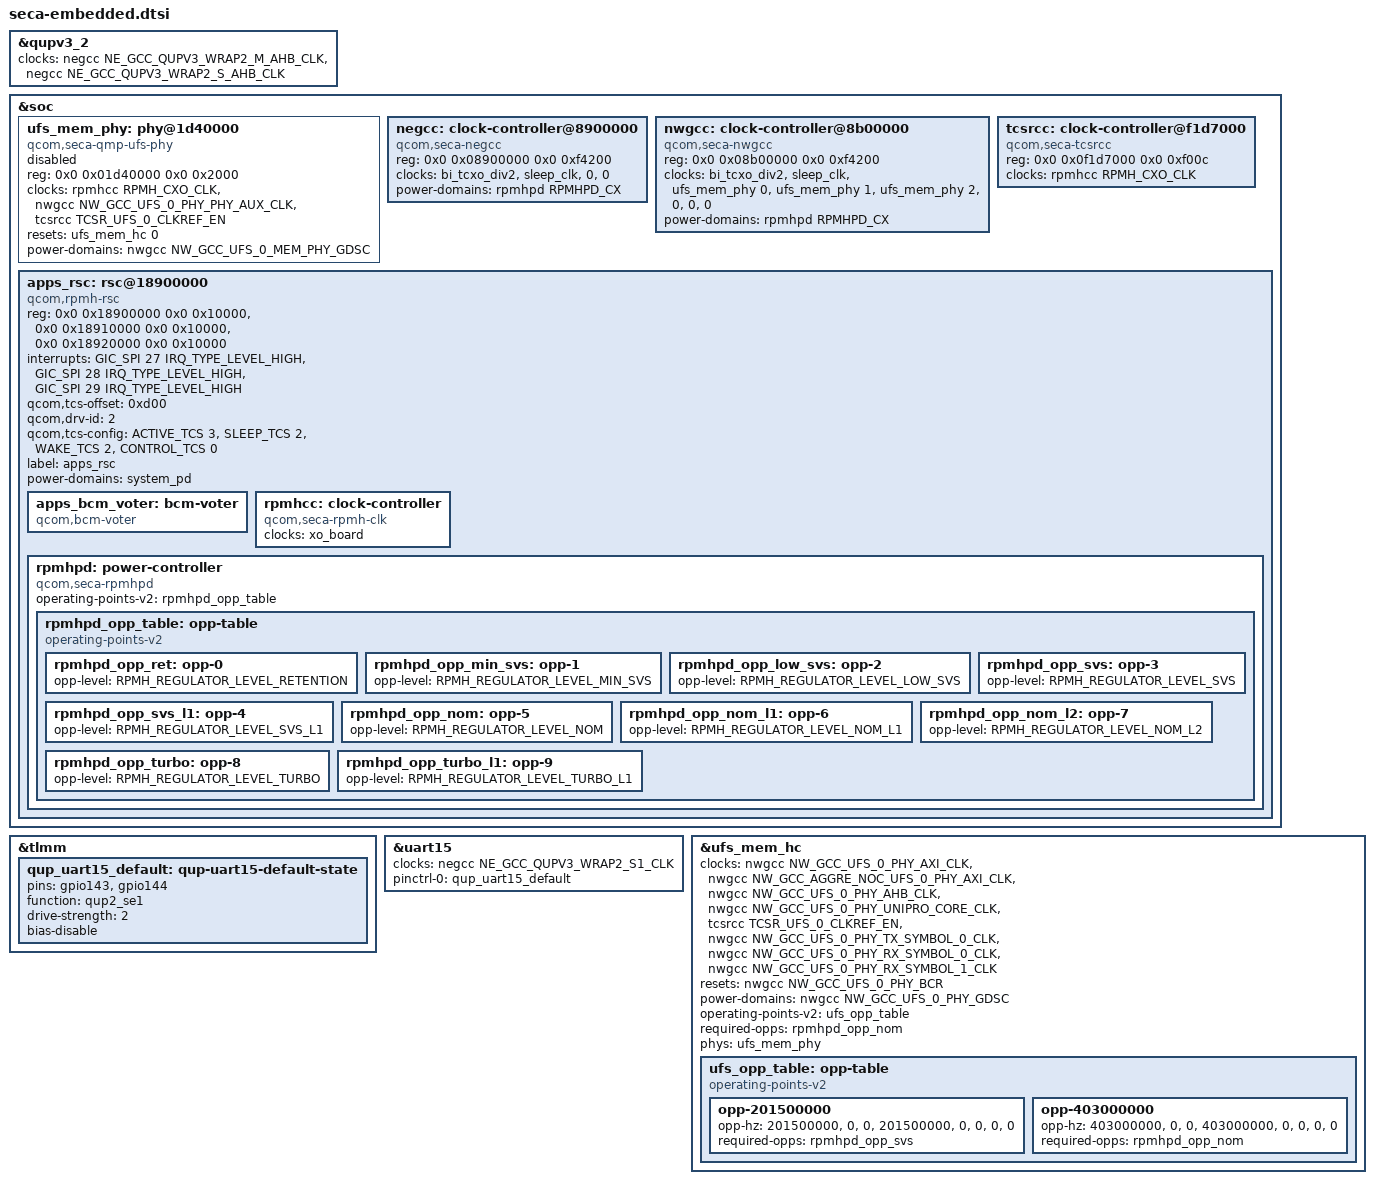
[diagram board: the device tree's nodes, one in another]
// SPDX-License-Identifier: BSD-3-Clause
/*
 * Copyright (c) Qualcomm Technologies, Inc. and/or its subsidiaries.
 */

#include <dt-bindings/clock/qcom,rpmh.h>
#include <dt-bindings/clock/qcom,seca-negcc.h>
#include <dt-bindings/clock/qcom,seca-nwgcc.h>
#include <dt-bindings/clock/qcom,seca-tcsrcc.h>
#include <dt-bindings/power/qcom,rpmhpd.h>
#include <dt-bindings/soc/qcom,rpmh-rsc.h>

#include "seca.dtsi"

&qupv3_2 {
	clocks = <&negcc NE_GCC_QUPV3_WRAP2_M_AHB_CLK>,
		 <&negcc NE_GCC_QUPV3_WRAP2_S_AHB_CLK>;
	clock-names = "m-ahb",
		      "s-ahb";
};

&soc {
	ufs_mem_phy: phy@1d40000 {
		compatible = "qcom,seca-qmp-ufs-phy",
			     "qcom,sm8650-qmp-ufs-phy";
		reg = <0x0 0x01d40000 0x0 0x2000>;

		clocks = <&rpmhcc RPMH_CXO_CLK>,
			 <&nwgcc NW_GCC_UFS_0_PHY_PHY_AUX_CLK>,
			 <&tcsrcc TCSR_UFS_0_CLKREF_EN>;
		clock-names = "ref",
			      "ref_aux",
			      "qref";

		resets = <&ufs_mem_hc 0>;
		reset-names = "ufsphy";

		power-domains = <&nwgcc NW_GCC_UFS_0_MEM_PHY_GDSC>;

		#clock-cells = <1>;
		#phy-cells = <0>;

		status = "disabled";
	};

	negcc: clock-controller@8900000 {
		compatible = "qcom,seca-negcc";
		reg = <0x0 0x08900000 0x0 0xf4200>;
		clocks = <&bi_tcxo_div2>,
			 <&sleep_clk>,
			 <0>,
			 <0>;
		power-domains = <&rpmhpd RPMHPD_CX>;
		#clock-cells = <1>;
		#reset-cells = <1>;
		#power-domain-cells = <1>;
	};

	nwgcc: clock-controller@8b00000 {
		compatible = "qcom,seca-nwgcc";
		reg = <0x0 0x08b00000 0x0 0xf4200>;
		clocks = <&bi_tcxo_div2>,
			 <&sleep_clk>,
			 <&ufs_mem_phy 0>,
			 <&ufs_mem_phy 1>,
			 <&ufs_mem_phy 2>,
			 <0>,
			 <0>,
			 <0>;
		power-domains = <&rpmhpd RPMHPD_CX>;
		#clock-cells = <1>;
		#reset-cells = <1>;
		#power-domain-cells = <1>;
	};

	tcsrcc: clock-controller@f1d7000 {
		compatible = "qcom,seca-tcsrcc";
		reg = <0x0 0x0f1d7000 0x0 0xf00c>;
		clocks = <&rpmhcc RPMH_CXO_CLK>;
		#clock-cells = <1>;
	};

	apps_rsc: rsc@18900000 {
		compatible = "qcom,rpmh-rsc";
		reg = <0x0 0x18900000 0x0 0x10000>,
		      <0x0 0x18910000 0x0 0x10000>,
		      <0x0 0x18920000 0x0 0x10000>;
		reg-names = "drv-0",
			    "drv-1",
			    "drv-2";
		interrupts = <GIC_SPI 27 IRQ_TYPE_LEVEL_HIGH>,
			     <GIC_SPI 28 IRQ_TYPE_LEVEL_HIGH>,
			     <GIC_SPI 29 IRQ_TYPE_LEVEL_HIGH>;
		qcom,tcs-offset = <0xd00>;
		qcom,drv-id = <2>;
		qcom,tcs-config = <ACTIVE_TCS 3>,
				  <SLEEP_TCS 2>,
				  <WAKE_TCS 2>,
				  <CONTROL_TCS 0>;
		label = "apps_rsc";
		power-domains = <&system_pd>;

		apps_bcm_voter: bcm-voter {
			compatible = "qcom,bcm-voter";
		};

		rpmhcc: clock-controller {
			compatible = "qcom,seca-rpmh-clk";
			clocks = <&xo_board>;
			clock-names = "xo";
			#clock-cells = <1>;
		};

		rpmhpd: power-controller {
			compatible = "qcom,seca-rpmhpd";
			#power-domain-cells = <1>;
			operating-points-v2 = <&rpmhpd_opp_table>;

			rpmhpd_opp_table: opp-table {
				compatible = "operating-points-v2";

				rpmhpd_opp_ret: opp-0 {
					opp-level = <RPMH_REGULATOR_LEVEL_RETENTION>;
				};

				rpmhpd_opp_min_svs: opp-1 {
					opp-level = <RPMH_REGULATOR_LEVEL_MIN_SVS>;
				};

				rpmhpd_opp_low_svs: opp-2 {
					opp-level = <RPMH_REGULATOR_LEVEL_LOW_SVS>;
				};

				rpmhpd_opp_svs: opp-3 {
					opp-level = <RPMH_REGULATOR_LEVEL_SVS>;
				};

				rpmhpd_opp_svs_l1: opp-4 {
					opp-level = <RPMH_REGULATOR_LEVEL_SVS_L1>;
				};

				rpmhpd_opp_nom: opp-5 {
					opp-level = <RPMH_REGULATOR_LEVEL_NOM>;
				};

				rpmhpd_opp_nom_l1: opp-6 {
					opp-level = <RPMH_REGULATOR_LEVEL_NOM_L1>;
				};

				rpmhpd_opp_nom_l2: opp-7 {
					opp-level = <RPMH_REGULATOR_LEVEL_NOM_L2>;
				};

				rpmhpd_opp_turbo: opp-8 {
					opp-level = <RPMH_REGULATOR_LEVEL_TURBO>;
				};

				rpmhpd_opp_turbo_l1: opp-9 {
					opp-level = <RPMH_REGULATOR_LEVEL_TURBO_L1>;
				};
			};
		};
	};
};

&tlmm {
	qup_uart15_default: qup-uart15-default-state {
		pins = "gpio143", "gpio144";
		function = "qup2_se1";
		drive-strength = <2>;
		bias-disable;
	};
};

&uart15 {
	clocks = <&negcc NE_GCC_QUPV3_WRAP2_S1_CLK>;
	clock-names = "se";

	pinctrl-0 = <&qup_uart15_default>;
	pinctrl-names = "default";
};

&ufs_mem_hc {
	clocks = <&nwgcc NW_GCC_UFS_0_PHY_AXI_CLK>,
		 <&nwgcc NW_GCC_AGGRE_NOC_UFS_0_PHY_AXI_CLK>,
		 <&nwgcc NW_GCC_UFS_0_PHY_AHB_CLK>,
		 <&nwgcc NW_GCC_UFS_0_PHY_UNIPRO_CORE_CLK>,
		 <&tcsrcc TCSR_UFS_0_CLKREF_EN>,
		 <&nwgcc NW_GCC_UFS_0_PHY_TX_SYMBOL_0_CLK>,
		 <&nwgcc NW_GCC_UFS_0_PHY_RX_SYMBOL_0_CLK>,
		 <&nwgcc NW_GCC_UFS_0_PHY_RX_SYMBOL_1_CLK>;
	clock-names = "core_clk",
		      "bus_aggr_clk",
		      "iface_clk",
		      "core_clk_unipro",
		      "ref_clk",
		      "tx_lane0_sync_clk",
		      "rx_lane0_sync_clk",
		      "rx_lane1_sync_clk";

	resets = <&nwgcc NW_GCC_UFS_0_PHY_BCR>;
	reset-names = "rst";

	power-domains = <&nwgcc NW_GCC_UFS_0_PHY_GDSC>;
	operating-points-v2 = <&ufs_opp_table>;
	required-opps = <&rpmhpd_opp_nom>;

	phys = <&ufs_mem_phy>;
	phy-names = "ufsphy";

	#reset-cells = <1>;

	ufs_opp_table: opp-table {
		compatible = "operating-points-v2";

		opp-201500000 {
			opp-hz = /bits/ 64 <201500000>,
				 /bits/ 64 <0>,
				 /bits/ 64 <0>,
				 /bits/ 64 <201500000>,
				 /bits/ 64 <0>,
				 /bits/ 64 <0>,
				 /bits/ 64 <0>,
				 /bits/ 64 <0>;
			required-opps = <&rpmhpd_opp_svs>;
		};

		opp-403000000 {
			opp-hz = /bits/ 64 <403000000>,
				 /bits/ 64 <0>,
				 /bits/ 64 <0>,
				 /bits/ 64 <403000000>,
				 /bits/ 64 <0>,
				 /bits/ 64 <0>,
				 /bits/ 64 <0>,
				 /bits/ 64 <0>;
			required-opps = <&rpmhpd_opp_nom>;
		};
	};
};
